# TREMO register map
File version: 1.6.2
CPU: CM4 r0p1, little endian, MPU, FPU, 3 interrupt priority bits
Registers are 32-bit, read-write, reset 0x0 unless marked. A register's access mark holds for its fields unless they carry their own. Offsets are from the block's base; [hi:lo] are bit positions.

## I2C0
Base 0x40007000
Same registers: I2C1 0x40014000
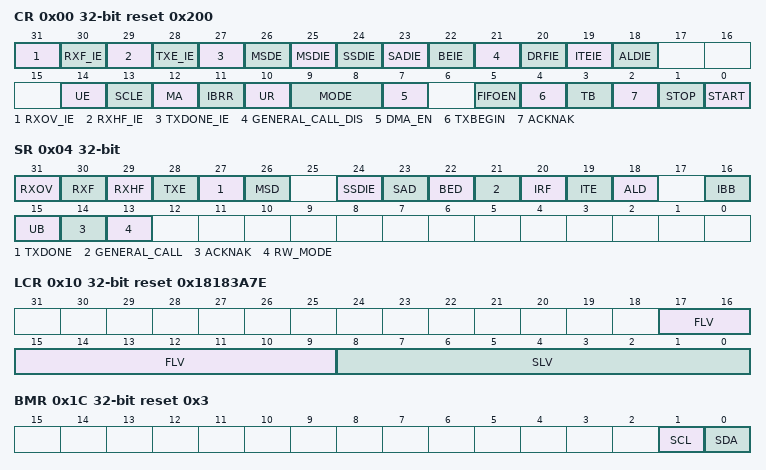
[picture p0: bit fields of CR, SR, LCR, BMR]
0x00 CR reset 0x200 — control register
  [31] RXOV_IE — Receive FIFO overrun interrupt enable
  [30] RXF_IE — Receive FIFO full interrupt enable
  [29] RXHF_IE — Receive FIFO half full interrupt enable
  [28] TXE_IE — Transmit FIFO empty interrupt enable
  [27] TXDONE_IE — Transaction done interrupt enable
  [26] MSDE — Master Stop detection enable
  [25] MSDIE — Master Stop detection interrupt enable
  [24] SSDIE — Slave Stop detection interrupt enable
  [23] SADIE — Slave address detection interrupt enable
  [22] BEIE — Bus error interrupt enable
  [21] GENERAL_CALL_DIS
  [20] DRFIE — I2Cx_DBR receive-full interrupt enable
  [19] ITEIE — I2Cx_DBR transmit-empty interrupt enable
  [18] ALDIE — Arbitration loss detection interrupt enable
  [14] UE — I2C unit enable
  [13] SCLE — SCL enable
  [12] MA — Master abort
  [11] IBRR — I2C bus reset request
  [10] UR — Unit reset
  [9:8] MODE — Bus clock mode for the master
  [7] DMA_EN — DMA enable
  [5] FIFOEN — FIFO mode enable
  [4] TXBEGIN — Transaction begin
  [3] TB — Transfer byte
  [2] ACKNAK — positive/negative acknowledge
  [1] STOP — Generate a Stop condition
  [0] START — Generate a Start condition
0x04 SR (reset mask 0xFBFDE000) — status register
  [31] RXOV — Receive FIFO overrun flag
  [30] RXF — Receive FIFO full flag
  [29] RXHF — Receive FIFO half-full flag
  [28] TXE — Transmit FIFO empty flag
  [27] TXDONE — Transaction done flag
  [26] MSD — Master Stop detection flag
  [24] SSDIE — Slave Stop detection flag
  [23] SAD — Slave address detection flag
  [22] BED — Bus error detection flag
  [21] GENERAL_CALL
  [20] IRF — I2Cx_DBR receive full flag
  [19] ITE — I2Cx_DBR transmit empty flag
  [18] ALD — Arbitration loss detection flag
  [16] IBB ro — I2C bus busy flag
  [15] UB ro — I2C unit busy flag
  [14] ACKNAK ro — ACK/NAK status flag
  [13] RW_MODE
0x08 SAR — slave address register
  [6:0] SLAVE_ADDRESS — ASR6601 I2C slave address used in slave mode
0x0C DBR — data buffer register
  [7:0] DATA_BUFFER — Buffer for I2C bus transmit/receive data
0x10 LCR reset 0x18183A7E — load count register
  [17:9] FLV — Phase decrementer load value for fast mode SCL in master mode
  [8:0] SLV — Phase decrementer load value for standard mode SCL in master mode
0x14 WCR reset 0x143A — wait count register
  [4:0] COUNT — Counter values for defining the setup and hold times in standard and fast modes
0x18 RST_CYCL — reset cycle register
  [3:0] RST_CYC — Serial bus reset SCL cycle count
0x1C BMR ro reset 0x3 — bus monitor register
  [1] SCL — SCL pin state
  [0] SDA — SDA pin state
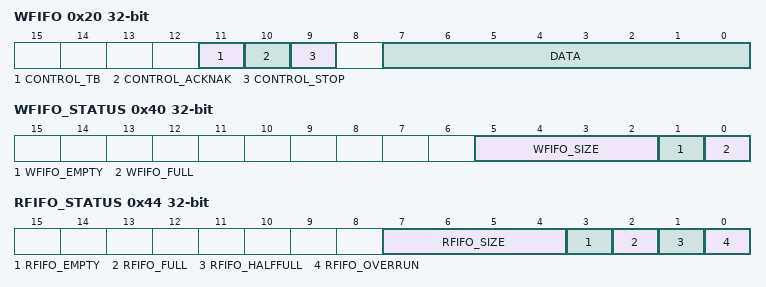
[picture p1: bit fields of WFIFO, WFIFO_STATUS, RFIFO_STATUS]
0x20 WFIFO wo — write fifo register
  [11] CONTROL_TB rw
  [10] CONTROL_ACKNAK rw
  [9] CONTROL_STOP rw
  [7:0] DATA — I2C bus send data for write transactions and dummy data for read transactions
0x24 WFIFO_WPTR — write fifo write pointer register
  [3:0] DATA
0x28 WFIFO_RPTR — write fifo read pointer register
  [3:0] DATA — The position in the Transmit FIFO where the hardware will read the next entry
0x2C RFIFO ro — read fifo register
  [7:0] DATA — bus receive data for read transactions
0x30 RFIFO_WPTR ro — read fifo write pointer register
  [3:0] DATA — position in the Receive FIFO where the hardware will write the next entry
0x34 RFIFO_RPTR ro — read fifo read pointer register
  [3:0] DATA — position in the Receive FIFO where the software will read the next entry
0x40 WFIFO_STATUS ro — write fifo status register
  [5:2] WFIFO_SIZE rw — The Transmit FIFO size
  [1] WFIFO_EMPTY — Transmit FIFO empty
  [0] WFIFO_FULL — Transmit FIFO full
0x44 RFIFO_STATUS ro — read fifo status register
  [7:4] RFIFO_SIZE — Receive FIFO size
  [3] RFIFO_EMPTY — Receive FIFO empty
  [2] RFIFO_FULL — Receive FIFO full
  [1] RFIFO_HALFFULL — Receive FIFO half full
  [0] RFIFO_OVERRUN — Receive FIFO overrun
